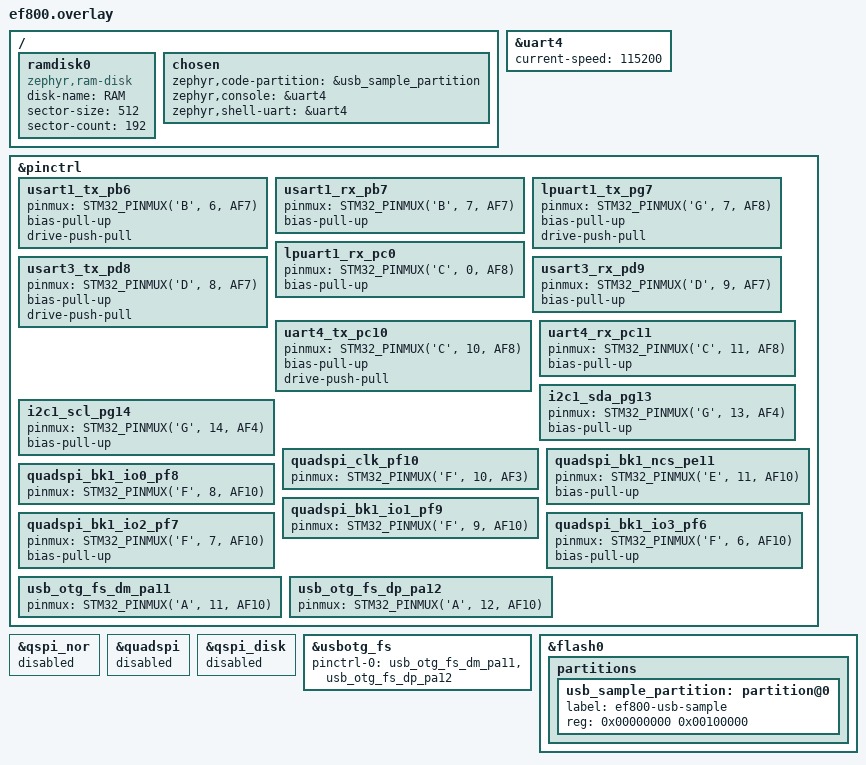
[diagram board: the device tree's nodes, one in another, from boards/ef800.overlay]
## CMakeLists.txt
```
# SPDX-License-Identifier: Apache-2.0
cmake_minimum_required(VERSION 3.20.0)

set(BOARD_ROOT ${CMAKE_CURRENT_LIST_DIR}/../..)

if(BOARD STREQUAL "nucleo_f767zi")
	set(DTC_OVERLAY_FILE ${CMAKE_CURRENT_LIST_DIR}/boards/nucleo_f767zi.overlay)
else()
	set(DTC_OVERLAY_FILE ${CMAKE_CURRENT_LIST_DIR}/boards/ef800.overlay)
endif()

find_package(Zephyr REQUIRED HINTS $ENV{ZEPHYR_BASE})
project(ef800_usb_sample)

target_sources(app PRIVATE src/main.c)
```

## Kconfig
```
# SPDX-License-Identifier: Apache-2.0

config EF800_USB_SAMPLE_WIPE_STORAGE
	bool "Erase external flash storage before mounting"
	default n
	help
		Erase only the external flash storage partition before mounting it.
		This is destructive and must be enabled only for a controlled test.

config EF800_USB_SAMPLE_VID
	hex "USB vendor ID"
	default 0x2fe3

config EF800_USB_SAMPLE_PID
	hex "USB product ID"
	default 0xef84

source "Kconfig.zephyr"
```

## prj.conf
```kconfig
# SPDX-License-Identifier: Apache-2.0

CONFIG_USE_DT_CODE_PARTITION=y
CONFIG_MAIN_STACK_SIZE=2048

CONFIG_DISK_DRIVERS=y

CONFIG_FILE_SYSTEM=y
CONFIG_FAT_FILESYSTEM_ELM=y
CONFIG_FS_FATFS_MOUNT_MKFS=y
CONFIG_FS_FATFS_LFN=y
CONFIG_FS_FATFS_LFN_MODE_STACK=y

CONFIG_USB_DEVICE_STACK_NEXT=y
CONFIG_USBD_MSC_CLASS=y
CONFIG_USBD_MSC_LUNS_PER_INSTANCE=1
CONFIG_USBD_MSC_SCSI_BUFFER_SIZE=512

CONFIG_SERIAL=y
CONFIG_UART_CONSOLE=y
CONFIG_CONSOLE=y
CONFIG_LOG=y
CONFIG_LOG_DEFAULT_LEVEL=3

CONFIG_EF800_USB_SAMPLE_VID=0x2fe3
CONFIG_EF800_USB_SAMPLE_PID=0xef84

# The Nucleo variant uses the board RAM disk instead of EF800 QSPI.
CONFIG_DISK_DRIVER_RAM=y
```

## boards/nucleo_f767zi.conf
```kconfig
# SPDX-License-Identifier: Apache-2.0

# Link directly from the MCU flash base. Do not use the Nucleo board's
# mcuboot/image slot partition layout for this standalone test image.
CONFIG_USE_DT_CODE_PARTITION=n
```

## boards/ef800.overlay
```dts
/* SPDX-License-Identifier: Apache-2.0 */

#include <zephyr/dt-bindings/pinctrl/stm32-pinctrl.h>

/ {
	ramdisk0 {
		compatible = "zephyr,ram-disk";
		disk-name = "RAM";
		sector-size = <512>;
		sector-count = <192>;
	};

	chosen {
		zephyr,code-partition = &usb_sample_partition;
		zephyr,console = &uart4;
		zephyr,shell-uart = &uart4;
	};
};

/* Keep the sample console separate from USB. */
&uart4 {
	current-speed = <115200>;
	status = "okay";
};

&pinctrl {
	usart1_tx_pb6: usart1_tx_pb6 {
		pinmux = <STM32_PINMUX('B', 6, AF7)>;
		bias-pull-up;
		drive-push-pull;
	};

	usart1_rx_pb7: usart1_rx_pb7 {
		pinmux = <STM32_PINMUX('B', 7, AF7)>;
		bias-pull-up;
	};

	lpuart1_tx_pg7: lpuart1_tx_pg7 {
		pinmux = <STM32_PINMUX('G', 7, AF8)>;
		bias-pull-up;
		drive-push-pull;
	};

	lpuart1_rx_pc0: lpuart1_rx_pc0 {
		pinmux = <STM32_PINMUX('C', 0, AF8)>;
		bias-pull-up;
	};

	usart3_tx_pd8: usart3_tx_pd8 {
		pinmux = <STM32_PINMUX('D', 8, AF7)>;
		bias-pull-up;
		drive-push-pull;
	};

	usart3_rx_pd9: usart3_rx_pd9 {
		pinmux = <STM32_PINMUX('D', 9, AF7)>;
		bias-pull-up;
	};

	uart4_tx_pc10: uart4_tx_pc10 {
		pinmux = <STM32_PINMUX('C', 10, AF8)>;
		bias-pull-up;
		drive-push-pull;
	};

	uart4_rx_pc11: uart4_rx_pc11 {
		pinmux = <STM32_PINMUX('C', 11, AF8)>;
		bias-pull-up;
	};

	i2c1_sda_pg13: i2c1_sda_pg13 {
		pinmux = <STM32_PINMUX('G', 13, AF4)>;
		bias-pull-up;
	};

	i2c1_scl_pg14: i2c1_scl_pg14 {
		pinmux = <STM32_PINMUX('G', 14, AF4)>;
		bias-pull-up;
	};

	quadspi_clk_pf10: quadspi_clk_pf10 {
		pinmux = <STM32_PINMUX('F', 10, AF3)>;
	};

	quadspi_bk1_ncs_pe11: quadspi_bk1_ncs_pe11 {
		pinmux = <STM32_PINMUX('E', 11, AF10)>;
		bias-pull-up;
	};

	quadspi_bk1_io0_pf8: quadspi_bk1_io0_pf8 {
		pinmux = <STM32_PINMUX('F', 8, AF10)>;
	};

	quadspi_bk1_io1_pf9: quadspi_bk1_io1_pf9 {
		pinmux = <STM32_PINMUX('F', 9, AF10)>;
	};

	quadspi_bk1_io2_pf7: quadspi_bk1_io2_pf7 {
		pinmux = <STM32_PINMUX('F', 7, AF10)>;
		bias-pull-up;
	};

	quadspi_bk1_io3_pf6: quadspi_bk1_io3_pf6 {
		pinmux = <STM32_PINMUX('F', 6, AF10)>;
		bias-pull-up;
	};

	usb_otg_fs_dm_pa11: usb_otg_fs_dm_pa11 {
		pinmux = <STM32_PINMUX('A', 11, AF10)>;
	};

	usb_otg_fs_dp_pa12: usb_otg_fs_dp_pa12 {
		pinmux = <STM32_PINMUX('A', 12, AF10)>;
	};

};

&qspi_nor {
	status = "disabled";
};

&quadspi {
	status = "disabled";
};

&qspi_disk {
	status = "disabled";
};

&usbotg_fs {
	pinctrl-0 = <&usb_otg_fs_dm_pa11 &usb_otg_fs_dp_pa12>;
	pinctrl-names = "default";
	status = "okay";
};

&flash0 {
	partitions {
		/delete-node/ partition@0;
		/delete-node/ partition@10000;
		/delete-node/ partition@20000;
		/delete-node/ partition@30000;

		usb_sample_partition: partition@0 {
			label = "ef800-usb-sample";
			reg = <0x00000000 0x00100000>;
		};
	};
};
```

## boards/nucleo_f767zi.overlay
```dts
/* SPDX-License-Identifier: Apache-2.0 */

/ {
	chosen {
		zephyr,console = &usart3;
		zephyr,shell-uart = &usart3;
		/delete-property/ zephyr,code-partition;
	};

	ramdisk0 {
		compatible = "zephyr,ram-disk";
		disk-name = "RAM";
		sector-size = <512>;
		sector-count = <192>;
	};
};

&zephyr_udc0 {
	status = "okay";
};

/* This standalone image owns the whole internal flash from 0x08000000. */
&flash0 {
	partitions {
		/delete-node/ partition@0;
		/delete-node/ partition@10000;
		/delete-node/ partition@40000;
		/delete-node/ partition@100000;
		/delete-node/ partition@1c0000;
	};
};
```

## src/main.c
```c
/* SPDX-License-Identifier: Apache-2.0 */
/** @file @brief Demonstrate USB device functionality on the EF800 platform. */

#include <errno.h>
#include <stdbool.h>
#include <stdio.h>

#include <zephyr/device.h>
#include <zephyr/fs/fs.h>
#include <zephyr/kernel.h>
#include <zephyr/logging/log.h>
#include <zephyr/storage/disk_access.h>
#include <zephyr/storage/flash_map.h>
#include <zephyr/usb/class/usbd_msc.h>
#include <zephyr/usb/usbd.h>
#include <ff.h>
#include <stm32l4xx.h>

LOG_MODULE_REGISTER(ef800_usb_sample, LOG_LEVEL_INF);

#define EF800_DISK_NAME "RAM"
#define EF800_MOUNT_POINT "/RAM:"
#define EF800_USB_UDC_NODE DT_NODELABEL(usbotg_fs)

#if DT_NODE_EXISTS(DT_NODELABEL(zephyr_udc0))
#undef EF800_USB_UDC_NODE
#define EF800_USB_UDC_NODE DT_NODELABEL(zephyr_udc0)
#endif

BUILD_ASSERT(DT_NODE_HAS_STATUS(EF800_USB_UDC_NODE, okay),
	"EF800 USB sample requires an enabled USB device controller");

USBD_DEVICE_DEFINE(ef800_usb_sample_usbd,
	DEVICE_DT_GET(EF800_USB_UDC_NODE),
	CONFIG_EF800_USB_SAMPLE_VID, CONFIG_EF800_USB_SAMPLE_PID);
USBD_DESC_LANG_DEFINE(ef800_usb_sample_lang);
USBD_DESC_MANUFACTURER_DEFINE(ef800_usb_sample_manufacturer, "EF800");
USBD_DESC_PRODUCT_DEFINE(ef800_usb_sample_product,
	"EF800 USB Mass Storage Sample");
USBD_DESC_CONFIG_DEFINE(ef800_usb_sample_config_desc, "EF800 MSC");
USBD_CONFIGURATION_DEFINE(ef800_usb_sample_config, 0, 125,
	&ef800_usb_sample_config_desc);
USBD_DEFINE_MSC_LUN(ef800_usb_sample_lun, EF800_DISK_NAME, "EF800",
	"USB Disk", "1.00");

static FATFS fat_fs;
static struct fs_mount_t mount = {
	.type = FS_FATFS,
	.mnt_point = EF800_MOUNT_POINT,
	.fs_data = &fat_fs,
	.flags = IS_ENABLED(CONFIG_DISK_DRIVER_RAM) ? 0 : FS_MOUNT_FLAG_NO_FORMAT,
};

static void setup_flash_mount(void)
{
}

static int setup_storage(void)
{
	int ret;

	printk("ef800_usb_sample: storage init disk=%s mount=%s\r\n",
		EF800_DISK_NAME, EF800_MOUNT_POINT);
	setup_flash_mount();

	ret = disk_access_init(EF800_DISK_NAME);
	if (ret != 0) {
		printk("ef800_usb_sample: disk init failed=%d\r\n", ret);
		LOG_ERR("disk init failed: %d", ret);
		return ret;
	}

#if CONFIG_EF800_USB_SAMPLE_WIPE_STORAGE && CONFIG_DISK_DRIVER_FLASH
	const struct flash_area *area;

	ret = flash_area_open(PARTITION_ID(qspi_storage_partition), &area);
	if (ret == 0) {
		LOG_INF("erasing QSPI storage partition (%u bytes)",
			(unsigned int)area->fa_size);
		ret = flash_area_erase(area, 0, area->fa_size);
		flash_area_close(area);
	}
	if (ret != 0) {
		LOG_ERR("QSPI erase failed: %d", ret);
		return ret;
	}
#endif

	ret = fs_mount(&mount);
	if (ret != 0) {
		printk("ef800_usb_sample: FAT mount failed=%d\r\n", ret);
		LOG_ERR("FAT mount failed: %d (no format attempted)", ret);
		return ret;
	}

	LOG_INF("FAT mounted at %s", mount.mnt_point);
	printk("ef800_usb_sample: FAT mounted\r\n");
	return 0;
}

static int setup_usb(void)
{
	int ret;

	printk("ef800_usb_sample: USB descriptor setup\r\n");
	ret = usbd_add_descriptor(&ef800_usb_sample_usbd,
		&ef800_usb_sample_lang);
	if (ret != 0) { printk("ef800_usb_sample: lang failed=%d\r\n", ret); return ret; }
	ret = usbd_add_descriptor(&ef800_usb_sample_usbd,
		&ef800_usb_sample_manufacturer);
	if (ret != 0) { printk("ef800_usb_sample: manufacturer failed=%d\r\n", ret); return ret; }
	ret = usbd_add_descriptor(&ef800_usb_sample_usbd,
		&ef800_usb_sample_product);
	if (ret != 0) { printk("ef800_usb_sample: product failed=%d\r\n", ret); return ret; }
	ret = usbd_add_configuration(&ef800_usb_sample_usbd, USBD_SPEED_FS,
		&ef800_usb_sample_config);
	if (ret != 0) { printk("ef800_usb_sample: config failed=%d\r\n", ret); return ret; }
	ret = usbd_register_all_classes(&ef800_usb_sample_usbd, USBD_SPEED_FS,
		1, NULL);
	if (ret != 0) { printk("ef800_usb_sample: class registration failed=%d\r\n", ret); return ret; }
	ret = usbd_init(&ef800_usb_sample_usbd);
	if (ret != 0) { printk("ef800_usb_sample: USB init failed=%d\r\n", ret); return ret; }
	printk("ef800_usb_sample: USB enable\r\n");
	ret = usbd_enable(&ef800_usb_sample_usbd);
	printk("ef800_usb_sample: USB enable result=%d\r\n", ret);
	printk("ef800_usb_sample: USB caps vbus=%s\r\n",
		usbd_can_detect_vbus(&ef800_usb_sample_usbd) ? "yes" : "no");
	printk("ef800_usb_sample: GPIOA IDR=0x%08x MODER=0x%08x AFR1=0x%08x\r\n",
		(unsigned int)GPIOA->IDR, (unsigned int)GPIOA->MODER,
		(unsigned int)GPIOA->AFR[1]);
	printk("ef800_usb_sample: RCC CCIPR=0x%08x AHB2ENR=0x%08x\r\n",
		(unsigned int)RCC->CCIPR, (unsigned int)RCC->AHB2ENR);
	printk("ef800_usb_sample: USB GAHBCFG=0x%08x GUSBCFG=0x%08x\r\n",
		(unsigned int)USB_OTG_FS->GAHBCFG,
		(unsigned int)USB_OTG_FS->GUSBCFG);
	return ret;
}

int main(void)
{
	const struct device *udc = DEVICE_DT_GET(EF800_USB_UDC_NODE);
	int ret;

	if (!device_is_ready(udc)) {
		printk("ef800_usb_sample: USB controller not ready\r\n");
		LOG_ERR("USB controller is not ready");
		return -ENODEV;
	}

	ret = setup_storage();
	if (ret != 0) {
		return ret;
	}

	ret = setup_usb();
	if (ret != 0) {
		LOG_ERR("USB MSC setup failed: %d", ret);
		return ret;
	}

	LOG_INF("EF800 USB MSC enabled; host may connect");
	printk("ef800_usb_sample: MSC active, connect host\r\n");
	while (true) {
		k_sleep(K_FOREVER);
	}
}
```
